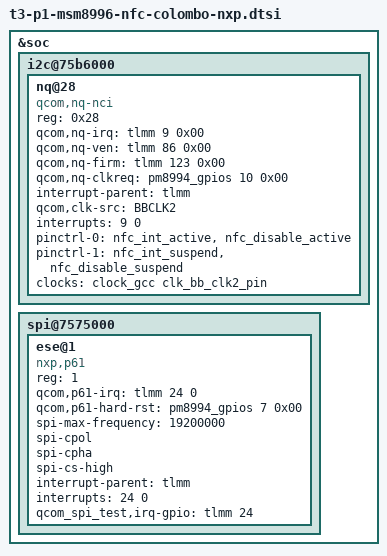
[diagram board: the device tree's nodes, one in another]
&soc {
/*
   i2c@75b6000 {
       status = "ok";

       nq@28 {
         compatible = "NXP,pn544";
         reg = <0x28>;
         qcom,nq-irq = <&tlmm 9 0x00>;
         qcom,nq-ven = <&tlmm 86 0x00>;
         qcom,nq-firm = <&tlmm 123 0x00>;
         qcom,nq-clkreq = <&pm8994_gpios 10 0x00>;
         interrupt-parent = <&tlmm>;
         qcom,clk-src = "BBCLK2";
         interrupts = <9 0>;
         interrupt-names = "nfc_irq";
         pinctrl-names = "nfc_active", "nfc_suspend";
         pinctrl-0 = <&nfc_int_active &nfc_disable_active>;
         pinctrl-1 = <&nfc_int_suspend &nfc_disable_suspend>;
         clocks = <&clock_gcc clk_bb_clk2_pin>;
         clock-names = "ref_clk";
     };
   };
*/

   i2c@75b6000 {
     status = "ok";

     nq@28 {
         compatible = "qcom,nq-nci";
         reg = <0x28>;
         qcom,nq-irq = <&tlmm 9 0x00>;
         qcom,nq-ven = <&tlmm 86 0x00>;
         qcom,nq-firm = <&tlmm 123 0x00>;
         qcom,nq-clkreq = <&pm8994_gpios 10 0x00>;
         interrupt-parent = <&tlmm>;
         qcom,clk-src = "BBCLK2";
         interrupts = <9 0>;
         interrupt-names = "nfc_irq";
         pinctrl-names = "nfc_active", "nfc_suspend";
         pinctrl-0 = <&nfc_int_active &nfc_disable_active>;
         pinctrl-1 = <&nfc_int_suspend &nfc_disable_suspend>;
         clocks = <&clock_gcc clk_bb_clk2_pin>;
         clock-names = "ref_clk";
     };
   };

    spi@7575000 { /* BLSP1 QUP1 */
        status = "ok";

        ese@1 {
           compatible = "nxp,p61"; /*Manufacture, and Model*/
           reg = <1>; /*Same as CS ID*/
           qcom,p61-irq = <&tlmm 24 0>;
           /*qcom,p61-rst = <&tlmm 42 0>;*/
           qcom,p61-hard-rst = <&pm8994_gpios 7 0x00>;
           spi-max-frequency = <19200000>;
           spi-cpol; /*CPOL bit set for SPI polarity*/
           spi-cpha; /*CPHA bit set for SPI Phase*/
           spi-cs-high; /*CS Active High*/
           interrupt-parent = <&tlmm>; /*GPIO Handler*/
           interrupts = <24 0>; /*GPIO # and flags*/
           qcom_spi_test,irq-gpio = <&tlmm 24 0x00>; /*Pass a GPIO*/
      };
    };
};
